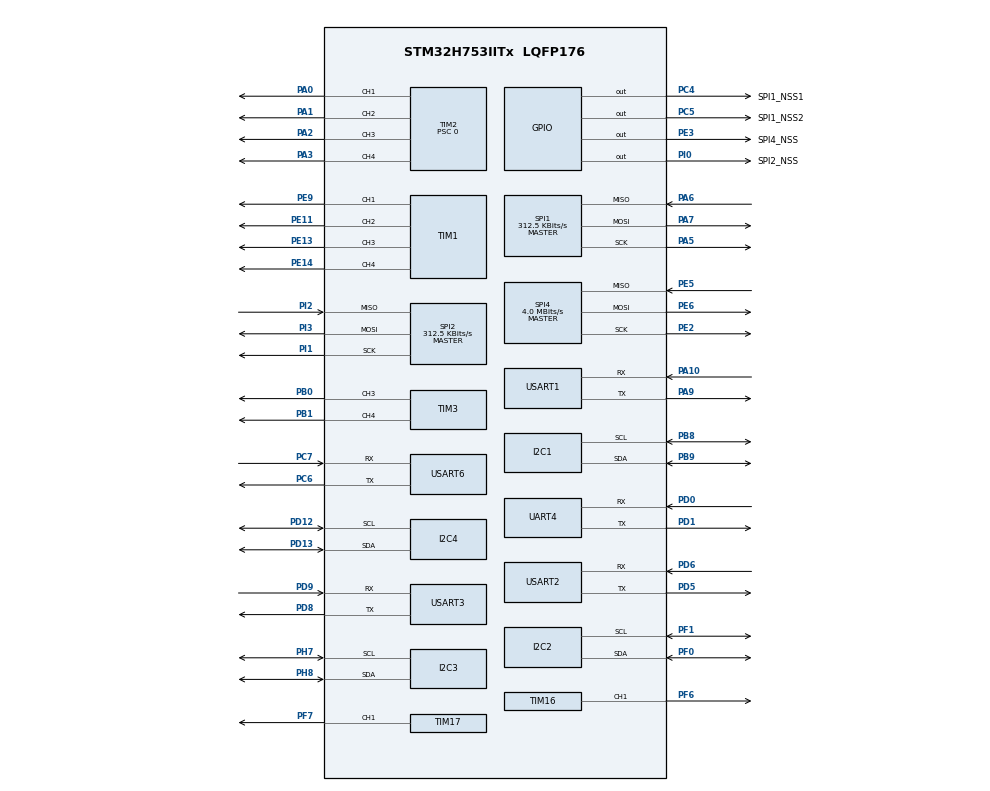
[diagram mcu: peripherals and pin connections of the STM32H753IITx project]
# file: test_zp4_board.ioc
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CORTEX_M7.default_mode_Activation=1
I2C1.I2C_Fall_Time=100
I2C1.I2C_Rise_Time=100
I2C1.Timing=0x00B07CB4
I2C2.I2C_Fall_Time=100
I2C2.I2C_Rise_Time=100
I2C2.Timing=0x00B07CB4
I2C3.I2C_Fall_Time=100
I2C3.I2C_Rise_Time=100
I2C3.Timing=0x00B07CB4
I2C4.I2C_Fall_Time=100
I2C4.I2C_Rise_Time=100
I2C4.Timing=0x00B07CB4
Mcu.Family=STM32H7
Mcu.Name=STM32H753IITx
Mcu.Package=LQFP176
NVIC.PriorityGroup=NVIC_PRIORITYGROUP_4
PA0.Signal=S_TIM2_CH1_ETR
PA1.Signal=S_TIM2_CH2
PA10.Mode=Asynchronous
PA10.Signal=USART1_RX
PA13\ (JTMS/SWDIO).Mode=Trace_Asynchronous_SW
PA13\ (JTMS/SWDIO).Signal=DEBUG_JTMS-SWDIO
PA14\ (JTCK/SWCLK).Mode=Trace_Asynchronous_SW
PA14\ (JTCK/SWCLK).Signal=DEBUG_JTCK-SWCLK
PA2.Signal=S_TIM2_CH3
PA3.Signal=S_TIM2_CH4
PA5.Mode=Full_Duplex_Master
PA5.Signal=SPI1_SCK
PA6.Mode=Full_Duplex_Master
PA6.Signal=SPI1_MISO
PA7.Mode=Full_Duplex_Master
PA7.Signal=SPI1_MOSI
PA9.Mode=Asynchronous
PA9.Signal=USART1_TX
PB0.Signal=S_TIM3_CH3
PB1.Signal=S_TIM3_CH4
PB3\ (JTDO/TRACESWO).Mode=Trace_Asynchronous_SW
PB3\ (JTDO/TRACESWO).Signal=DEBUG_JTDO-SWO
PB8.Mode=I2C
PB8.Signal=I2C1_SCL
PB9.Mode=I2C
PB9.Signal=I2C1_SDA
PC4.GPIO_Label=SPI1_NSS1
PC4.PinState=GPIO_PIN_SET
PC4.Signal=GPIO_Output
PC5.GPIO_Label=SPI1_NSS2
PC5.PinState=GPIO_PIN_SET
PC5.Signal=GPIO_Output
PC6.Mode=Asynchronous
PC6.Signal=USART6_TX
PC7.Mode=Asynchronous
PC7.Signal=USART6_RX
PD0.Mode=Asynchronous
PD0.Signal=UART4_RX
PD1.Mode=Asynchronous
PD1.Signal=UART4_TX
PD12.Mode=I2C
PD12.Signal=I2C4_SCL
PD13.Mode=I2C
PD13.Signal=I2C4_SDA
PD5.Mode=Asynchronous
PD5.Signal=USART2_TX
PD6.Mode=Asynchronous
PD6.Signal=USART2_RX
PD8.Mode=Asynchronous
PD8.Signal=USART3_TX
PD9.Mode=Asynchronous
PD9.Signal=USART3_RX
PE11.Signal=S_TIM1_CH2
PE13.Signal=S_TIM1_CH3
PE14.Signal=S_TIM1_CH4
PE2.Mode=Full_Duplex_Master
PE2.Signal=SPI4_SCK
PE3.GPIO_Label=SPI4_NSS
PE3.PinState=GPIO_PIN_SET
PE3.Signal=GPIO_Output
PE5.Mode=Full_Duplex_Master
PE5.Signal=SPI4_MISO
PE6.Mode=Full_Duplex_Master
PE6.Signal=SPI4_MOSI
PE9.Signal=S_TIM1_CH1
PF0.Mode=I2C
PF0.Signal=I2C2_SDA
PF1.Mode=I2C
PF1.Signal=I2C2_SCL
PF6.Signal=S_TIM16_CH1
PF7.Signal=S_TIM17_CH1
PH7.Mode=I2C
PH7.Signal=I2C3_SCL
PH8.Mode=I2C
PH8.Signal=I2C3_SDA
PI0.GPIO_Label=SPI2_NSS
PI0.PinState=GPIO_PIN_SET
PI0.Signal=GPIO_Output
PI1.Mode=Full_Duplex_Master
PI1.Signal=SPI2_SCK
PI2.Mode=Full_Duplex_Master
PI2.Signal=SPI2_MISO
PI3.Mode=Full_Duplex_Master
PI3.Signal=SPI2_MOSI
ProjectManager.HeapSize=0x200
ProjectManager.StackSize=0x400
ProjectManager.TargetToolchain=STM32CubeIDE
RCC.ADCFreq_Value=129000000
RCC.APB1Freq_Value=32000000
RCC.APB2Freq_Value=32000000
RCC.APB3Freq_Value=64000000
RCC.APB4Freq_Value=32000000
RCC.CortexFreq_Value=64000000
RCC.D2PPRE1=RCC_APB1_DIV2
RCC.D2PPRE2=RCC_APB2_DIV2
RCC.D3PPRE=RCC_APB4_DIV2
RCC.DATA_CACHE_ENABLE=0
RCC.DIVM1=4
RCC.DIVN1=10
RCC.HCLKFreq_Value=64000000
RCC.INSTRUCTION_CACHE_ENABLE=0
RCC.MSIAutoCalibration=DISABLED
RCC.MSICalibrationValue=0
RCC.PLLFRACN=0
RCC.PREFETCH_ENABLE=1
RCC.SYSCLKFreq_VALUE=64000000
RCC.USBFreq_Value=80000000
SH.S_TIM16_CH1.0=TIM16_CH1,PWM Generation1 CH1
SH.S_TIM17_CH1.0=TIM17_CH1,Output Compare1 CH1
SH.S_TIM1_CH1.0=TIM1_CH1,PWM Generation1 CH1
SH.S_TIM1_CH2.0=TIM1_CH2,PWM Generation2 CH2
SH.S_TIM1_CH3.0=TIM1_CH3,PWM Generation3 CH3
SH.S_TIM1_CH4.0=TIM1_CH4,PWM Generation4 CH4
SH.S_TIM2_CH1_ETR.0=TIM2_CH1,PWM Generation1 CH1
SH.S_TIM2_CH2.0=TIM2_CH2,PWM Generation2 CH2
SH.S_TIM2_CH3.0=TIM2_CH3,PWM Generation3 CH3
SH.S_TIM2_CH4.0=TIM2_CH4,PWM Generation4 CH4
SH.S_TIM3_CH3.0=TIM3_CH3,PWM Generation3 CH3
SH.S_TIM3_CH4.0=TIM3_CH4,PWM Generation4 CH4
SPI1.BaudRatePrescaler=SPI_BAUDRATEPRESCALER_256
SPI1.CalculateBaudRate=312.5 KBits/s
SPI1.DataSize=SPI_DATASIZE_8BIT
SPI1.Direction=SPI_DIRECTION_2LINES
SPI1.Mode=SPI_MODE_MASTER
SPI1.VirtualType=VM_MASTER
SPI2.BaudRatePrescaler=SPI_BAUDRATEPRESCALER_256
SPI2.CalculateBaudRate=312.5 KBits/s
SPI2.DataSize=SPI_DATASIZE_8BIT
SPI2.Direction=SPI_DIRECTION_2LINES
SPI2.Mode=SPI_MODE_MASTER
SPI2.VirtualType=VM_MASTER
SPI4.BaudRatePrescaler=SPI_BAUDRATEPRESCALER_8
SPI4.CLKPhase=SPI_PHASE_2EDGE
SPI4.CLKPolarity=SPI_POLARITY_HIGH
SPI4.CalculateBaudRate=4.0 MBits/s
SPI4.DataSize=SPI_DATASIZE_8BIT
SPI4.Direction=SPI_DIRECTION_2LINES
SPI4.FirstBit=SPI_FIRSTBIT_LSB
SPI4.Mode=SPI_MODE_MASTER
SPI4.VirtualType=VM_MASTER
TIM1.Channel-PWM\ Generation1\ CH1=TIM_CHANNEL_1
TIM1.Channel-PWM\ Generation2\ CH2=TIM_CHANNEL_2
TIM1.Channel-PWM\ Generation3\ CH3=TIM_CHANNEL_3
TIM1.Channel-PWM\ Generation4\ CH4=TIM_CHANNEL_4
TIM16.Channel=TIM_CHANNEL_1
TIM17.Channel=TIM_CHANNEL_1
TIM2.Channel-PWM\ Generation1\ CH1=TIM_CHANNEL_1
TIM2.Channel-PWM\ Generation2\ CH2=TIM_CHANNEL_2
TIM2.Channel-PWM\ Generation3\ CH3=TIM_CHANNEL_3
TIM2.Channel-PWM\ Generation4\ CH4=TIM_CHANNEL_4
TIM2.Prescaler=0
TIM3.Channel-PWM\ Generation3\ CH3=TIM_CHANNEL_3
TIM3.Channel-PWM\ Generation4\ CH4=TIM_CHANNEL_4
USART1.VirtualMode-Asynchronous=VM_ASYNC
USART2.VirtualMode-Asynchronous=VM_ASYNC
USART3.VirtualMode-Asynchronous=VM_ASYNC
USART6.VirtualMode-Asynchronous=VM_ASYNC
VP_MEMORYMAP_VS_MEMORYMAP.Mode=CurAppReg
VP_TIM16_VS_ClockSourceINT.Mode=Enable_Timer
VP_TIM17_VS_ClockSourceINT.Mode=Enable_Timer
VP_TIM1_VS_ClockSourceINT.Mode=Internal
VP_TIM2_VS_ClockSourceINT.Mode=Internal
VP_TIM3_VS_ClockSourceINT.Mode=Internal
board=custom

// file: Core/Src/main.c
/* USER CODE BEGIN Header */
/**
  ******************************************************************************
  * @file           : main.c
  * @brief          : Main program body
  ******************************************************************************
  * @attention
  *
  * Copyright (c) 2025 STMicroelectronics.
  * All rights reserved.
  *
  * This software is licensed under terms that can be found in the LICENSE file
  * in the root directory of this software component.
  * If no LICENSE file comes with this software, it is provided AS-IS.
  *
  ******************************************************************************
  */
/* USER CODE END Header */
#include "main.h"

I2C_HandleTypeDef hi2c1;
I2C_HandleTypeDef hi2c2;
I2C_HandleTypeDef hi2c3;
I2C_HandleTypeDef hi2c4;

SPI_HandleTypeDef hspi1;
SPI_HandleTypeDef hspi2;
SPI_HandleTypeDef hspi4;

TIM_HandleTypeDef htim1;
TIM_HandleTypeDef htim2;
TIM_HandleTypeDef htim3;
TIM_HandleTypeDef htim16;
TIM_HandleTypeDef htim17;

UART_HandleTypeDef huart4;
UART_HandleTypeDef huart1;
UART_HandleTypeDef huart2;
UART_HandleTypeDef huart3;
UART_HandleTypeDef huart6;

void SystemClock_Config(void);
static void MPU_Config(void);
static void MX_GPIO_Init(void);
static void MX_I2C1_Init(void);
static void MX_I2C2_Init(void);
static void MX_I2C3_Init(void);
static void MX_TIM1_Init(void);
static void MX_TIM2_Init(void);
static void MX_TIM3_Init(void);
static void MX_UART4_Init(void);
static void MX_USART1_UART_Init(void);
static void MX_USART2_UART_Init(void);
static void MX_USART3_UART_Init(void);
static void MX_USART6_UART_Init(void);
static void MX_SPI1_Init(void);
static void MX_SPI2_Init(void);
static void MX_SPI4_Init(void);
static void MX_TIM16_Init(void);
static void MX_TIM17_Init(void);
static void MX_I2C4_Init(void);

int main(void)
{

  /* MPU Configuration--------------------------------------------------------*/
  MPU_Config();

  /* MCU Configuration--------------------------------------------------------*/

  /* Reset of all peripherals, Initializes the Flash interface and the Systick. */
  HAL_Init();

  /* Configure the system clock */
  SystemClock_Config();

  /* Initialize all configured peripherals */
  MX_GPIO_Init();
  MX_I2C1_Init();
  MX_I2C2_Init();
  MX_I2C3_Init();
  MX_TIM1_Init();
  MX_TIM2_Init();
  MX_TIM3_Init();
  MX_UART4_Init();
  MX_USART1_UART_Init();
  MX_USART2_UART_Init();
  MX_USART3_UART_Init();
  MX_USART6_UART_Init();
  MX_SPI1_Init();
  MX_SPI2_Init();
  MX_SPI4_Init();
  MX_TIM16_Init();
  MX_TIM17_Init();
  MX_I2C4_Init();
  /* USER CODE BEGIN 2 */
  //testTimers();
  /* USER CODE END 2 */

  /* Infinite loop */
  /* USER CODE BEGIN WHILE */
  while (1)
  {
	  //testI2CTx(&hi2c1);    //I2C Testing (Transmit)
	  //testI2CRx(&hi2c1);    //I2C Testing (Receive)

	  // Example: testing SPI1 with two different slaves
	  //testSPI(&hspi1, SPI1_NSS1_GPIO_Port, SPI1_NSS1_Pin);
	  //testSPI(&hspi1, SPI1_NSS2_GPIO_Port, SPI1_NSS2_Pin);
	  //testSPI(&hspi2, SPI2_NSS_GPIO_Port, SPI2_NSS_Pin);
	  //testSPI(&hspi4, SPI4_NSS_GPIO_Port, SPI4_NSS_Pin);
	  //testUART(&huart4);
	  HAL_Delay(1000);
    /* USER CODE END WHILE */

  }
}

void SystemClock_Config(void)
{
  RCC_OscInitTypeDef RCC_OscInitStruct = {0};
  RCC_ClkInitTypeDef RCC_ClkInitStruct = {0};

  /** Supply configuration update enable
  */
  HAL_PWREx_ConfigSupply(PWR_LDO_SUPPLY);

  /** Configure the main internal regulator output voltage
  */
  __HAL_PWR_VOLTAGESCALING_CONFIG(PWR_REGULATOR_VOLTAGE_SCALE3);

  while(!__HAL_PWR_GET_FLAG(PWR_FLAG_VOSRDY)) {}

  /** Initializes the RCC Oscillators according to the specified parameters
  * in the RCC_OscInitTypeDef structure.
  */
  RCC_OscInitStruct.OscillatorType = RCC_OSCILLATORTYPE_HSI;
  RCC_OscInitStruct.HSIState = RCC_HSI_DIV1;
  RCC_OscInitStruct.HSICalibrationValue = RCC_HSICALIBRATION_DEFAULT;
  RCC_OscInitStruct.PLL.PLLState = RCC_PLL_ON;
  RCC_OscInitStruct.PLL.PLLSource = RCC_PLLSOURCE_HSI;
  RCC_OscInitStruct.PLL.PLLM = 4;
  RCC_OscInitStruct.PLL.PLLN = 10;
  RCC_OscInitStruct.PLL.PLLP = 2;
  RCC_OscInitStruct.PLL.PLLQ = 2;
  RCC_OscInitStruct.PLL.PLLR = 2;
  RCC_OscInitStruct.PLL.PLLRGE = RCC_PLL1VCIRANGE_3;
  RCC_OscInitStruct.PLL.PLLVCOSEL = RCC_PLL1VCOMEDIUM;
  RCC_OscInitStruct.PLL.PLLFRACN = 0;
  if (HAL_RCC_OscConfig(&RCC_OscInitStruct) != HAL_OK)
  {
    Error_Handler();
  }

  /** Initializes the CPU, AHB and APB buses clocks
  */
  RCC_ClkInitStruct.ClockType = RCC_CLOCKTYPE_HCLK|RCC_CLOCKTYPE_SYSCLK
                              |RCC_CLOCKTYPE_PCLK1|RCC_CLOCKTYPE_PCLK2
                              |RCC_CLOCKTYPE_D3PCLK1|RCC_CLOCKTYPE_D1PCLK1;
  RCC_ClkInitStruct.SYSCLKSource = RCC_SYSCLKSOURCE_HSI;
  RCC_ClkInitStruct.SYSCLKDivider = RCC_SYSCLK_DIV1;
  RCC_ClkInitStruct.AHBCLKDivider = RCC_HCLK_DIV1;
  RCC_ClkInitStruct.APB3CLKDivider = RCC_APB3_DIV1;
  RCC_ClkInitStruct.APB1CLKDivider = RCC_APB1_DIV2;
  RCC_ClkInitStruct.APB2CLKDivider = RCC_APB2_DIV2;
  RCC_ClkInitStruct.APB4CLKDivider = RCC_APB4_DIV2;

  if (HAL_RCC_ClockConfig(&RCC_ClkInitStruct, FLASH_LATENCY_1) != HAL_OK)
  {
    Error_Handler();
  }
}

static void MX_I2C1_Init(void)
{

  hi2c1.Instance = I2C1;
  hi2c1.Init.Timing = 0x00B07CB4;
  hi2c1.Init.OwnAddress1 = 0;
  hi2c1.Init.AddressingMode = I2C_ADDRESSINGMODE_7BIT;
  hi2c1.Init.DualAddressMode = I2C_DUALADDRESS_DISABLE;
  hi2c1.Init.OwnAddress2 = 0;
  hi2c1.Init.OwnAddress2Masks = I2C_OA2_NOMASK;
  hi2c1.Init.GeneralCallMode = I2C_GENERALCALL_DISABLE;
  hi2c1.Init.NoStretchMode = I2C_NOSTRETCH_DISABLE;
  if (HAL_I2C_Init(&hi2c1) != HAL_OK)
  {
    Error_Handler();
  }

  /** Configure Analogue filter
  */
  if (HAL_I2CEx_ConfigAnalogFilter(&hi2c1, I2C_ANALOGFILTER_ENABLE) != HAL_OK)
  {
    Error_Handler();
  }

  /** Configure Digital filter
  */
  if (HAL_I2CEx_ConfigDigitalFilter(&hi2c1, 0) != HAL_OK)
  {
    Error_Handler();
  }

}

static void MX_I2C2_Init(void)
{

  hi2c2.Instance = I2C2;
  hi2c2.Init.Timing = 0x00B07CB4;
  hi2c2.Init.OwnAddress1 = 0;
  hi2c2.Init.AddressingMode = I2C_ADDRESSINGMODE_7BIT;
  hi2c2.Init.DualAddressMode = I2C_DUALADDRESS_DISABLE;
  hi2c2.Init.OwnAddress2 = 0;
  hi2c2.Init.OwnAddress2Masks = I2C_OA2_NOMASK;
  hi2c2.Init.GeneralCallMode = I2C_GENERALCALL_DISABLE;
  hi2c2.Init.NoStretchMode = I2C_NOSTRETCH_DISABLE;
  if (HAL_I2C_Init(&hi2c2) != HAL_OK)
  {
    Error_Handler();
  }

  /** Configure Analogue filter
  */
  if (HAL_I2CEx_ConfigAnalogFilter(&hi2c2, I2C_ANALOGFILTER_ENABLE) != HAL_OK)
  {
    Error_Handler();
  }

  /** Configure Digital filter
  */
  if (HAL_I2CEx_ConfigDigitalFilter(&hi2c2, 0) != HAL_OK)
  {
    Error_Handler();
  }

}

static void MX_I2C3_Init(void)
{

  hi2c3.Instance = I2C3;
  hi2c3.Init.Timing = 0x00B07CB4;
  hi2c3.Init.OwnAddress1 = 0;
  hi2c3.Init.AddressingMode = I2C_ADDRESSINGMODE_7BIT;
  hi2c3.Init.DualAddressMode = I2C_DUALADDRESS_DISABLE;
  hi2c3.Init.OwnAddress2 = 0;
  hi2c3.Init.OwnAddress2Masks = I2C_OA2_NOMASK;
  hi2c3.Init.GeneralCallMode = I2C_GENERALCALL_DISABLE;
  hi2c3.Init.NoStretchMode = I2C_NOSTRETCH_DISABLE;
  if (HAL_I2C_Init(&hi2c3) != HAL_OK)
  {
    Error_Handler();
  }

  /** Configure Analogue filter
  */
  if (HAL_I2CEx_ConfigAnalogFilter(&hi2c3, I2C_ANALOGFILTER_ENABLE) != HAL_OK)
  {
    Error_Handler();
  }

  /** Configure Digital filter
  */
  if (HAL_I2CEx_ConfigDigitalFilter(&hi2c3, 0) != HAL_OK)
  {
    Error_Handler();
  }

}

static void MX_I2C4_Init(void)
{

  hi2c4.Instance = I2C4;
  hi2c4.Init.Timing = 0x00B07CB4;
  hi2c4.Init.OwnAddress1 = 0;
  hi2c4.Init.AddressingMode = I2C_ADDRESSINGMODE_7BIT;
  hi2c4.Init.DualAddressMode = I2C_DUALADDRESS_DISABLE;
  hi2c4.Init.OwnAddress2 = 0;
  hi2c4.Init.OwnAddress2Masks = I2C_OA2_NOMASK;
  hi2c4.Init.GeneralCallMode = I2C_GENERALCALL_DISABLE;
  hi2c4.Init.NoStretchMode = I2C_NOSTRETCH_DISABLE;
  if (HAL_I2C_Init(&hi2c4) != HAL_OK)
  {
    Error_Handler();
  }

  /** Configure Analogue filter
  */
  if (HAL_I2CEx_ConfigAnalogFilter(&hi2c4, I2C_ANALOGFILTER_ENABLE) != HAL_OK)
  {
    Error_Handler();
  }

  /** Configure Digital filter
  */
  if (HAL_I2CEx_ConfigDigitalFilter(&hi2c4, 0) != HAL_OK)
  {
    Error_Handler();
  }

}

static void MX_SPI1_Init(void)
{

  /* SPI1 parameter configuration*/
  hspi1.Instance = SPI1;
  hspi1.Init.Mode = SPI_MODE_MASTER;
  hspi1.Init.Direction = SPI_DIRECTION_2LINES;
  hspi1.Init.DataSize = SPI_DATASIZE_8BIT;
  hspi1.Init.CLKPolarity = SPI_POLARITY_LOW;
  hspi1.Init.CLKPhase = SPI_PHASE_1EDGE;
  hspi1.Init.NSS = SPI_NSS_SOFT;
  hspi1.Init.BaudRatePrescaler = SPI_BAUDRATEPRESCALER_256;
  hspi1.Init.FirstBit = SPI_FIRSTBIT_MSB;
  hspi1.Init.TIMode = SPI_TIMODE_DISABLE;
  hspi1.Init.CRCCalculation = SPI_CRCCALCULATION_DISABLE;
  hspi1.Init.CRCPolynomial = 0x0;
  hspi1.Init.NSSPMode = SPI_NSS_PULSE_ENABLE;
  hspi1.Init.NSSPolarity = SPI_NSS_POLARITY_LOW;
  hspi1.Init.FifoThreshold = SPI_FIFO_THRESHOLD_01DATA;
  hspi1.Init.TxCRCInitializationPattern = SPI_CRC_INITIALIZATION_ALL_ZERO_PATTERN;
  hspi1.Init.RxCRCInitializationPattern = SPI_CRC_INITIALIZATION_ALL_ZERO_PATTERN;
  hspi1.Init.MasterSSIdleness = SPI_MASTER_SS_IDLENESS_00CYCLE;
  hspi1.Init.MasterInterDataIdleness = SPI_MASTER_INTERDATA_IDLENESS_00CYCLE;
  hspi1.Init.MasterReceiverAutoSusp = SPI_MASTER_RX_AUTOSUSP_DISABLE;
  hspi1.Init.MasterKeepIOState = SPI_MASTER_KEEP_IO_STATE_DISABLE;
  hspi1.Init.IOSwap = SPI_IO_SWAP_DISABLE;
  if (HAL_SPI_Init(&hspi1) != HAL_OK)
  {
    Error_Handler();
  }

}

static void MX_SPI2_Init(void)
{

  /* SPI2 parameter configuration*/
  hspi2.Instance = SPI2;
  hspi2.Init.Mode = SPI_MODE_MASTER;
  hspi2.Init.Direction = SPI_DIRECTION_2LINES;
  hspi2.Init.DataSize = SPI_DATASIZE_8BIT;
  hspi2.Init.CLKPolarity = SPI_POLARITY_LOW;
  hspi2.Init.CLKPhase = SPI_PHASE_1EDGE;
  hspi2.Init.NSS = SPI_NSS_SOFT;
  hspi2.Init.BaudRatePrescaler = SPI_BAUDRATEPRESCALER_256;
  hspi2.Init.FirstBit = SPI_FIRSTBIT_MSB;
  hspi2.Init.TIMode = SPI_TIMODE_DISABLE;
  hspi2.Init.CRCCalculation = SPI_CRCCALCULATION_DISABLE;
  hspi2.Init.CRCPolynomial = 0x0;
  hspi2.Init.NSSPMode = SPI_NSS_PULSE_ENABLE;
  hspi2.Init.NSSPolarity = SPI_NSS_POLARITY_LOW;
  hspi2.Init.FifoThreshold = SPI_FIFO_THRESHOLD_01DATA;
  hspi2.Init.TxCRCInitializationPattern = SPI_CRC_INITIALIZATION_ALL_ZERO_PATTERN;
  hspi2.Init.RxCRCInitializationPattern = SPI_CRC_INITIALIZATION_ALL_ZERO_PATTERN;
  hspi2.Init.MasterSSIdleness = SPI_MASTER_SS_IDLENESS_00CYCLE;
  hspi2.Init.MasterInterDataIdleness = SPI_MASTER_INTERDATA_IDLENESS_00CYCLE;
  hspi2.Init.MasterReceiverAutoSusp = SPI_MASTER_RX_AUTOSUSP_DISABLE;
  hspi2.Init.MasterKeepIOState = SPI_MASTER_KEEP_IO_STATE_DISABLE;
  hspi2.Init.IOSwap = SPI_IO_SWAP_DISABLE;
  if (HAL_SPI_Init(&hspi2) != HAL_OK)
  {
    Error_Handler();
  }

}

static void MX_SPI4_Init(void)
{

  /* SPI4 parameter configuration*/
  hspi4.Instance = SPI4;
  hspi4.Init.Mode = SPI_MODE_MASTER;
  hspi4.Init.Direction = SPI_DIRECTION_2LINES;
  hspi4.Init.DataSize = SPI_DATASIZE_8BIT;
  hspi4.Init.CLKPolarity = SPI_POLARITY_HIGH;
  hspi4.Init.CLKPhase = SPI_PHASE_2EDGE;
  hspi4.Init.NSS = SPI_NSS_SOFT;
  hspi4.Init.BaudRatePrescaler = SPI_BAUDRATEPRESCALER_8;
  hspi4.Init.FirstBit = SPI_FIRSTBIT_LSB;
  hspi4.Init.TIMode = SPI_TIMODE_DISABLE;
  hspi4.Init.CRCCalculation = SPI_CRCCALCULATION_DISABLE;
  hspi4.Init.CRCPolynomial = 0x0;
  hspi4.Init.NSSPMode = SPI_NSS_PULSE_ENABLE;
  hspi4.Init.NSSPolarity = SPI_NSS_POLARITY_LOW;
  hspi4.Init.FifoThreshold = SPI_FIFO_THRESHOLD_01DATA;
  hspi4.Init.TxCRCInitializationPattern = SPI_CRC_INITIALIZATION_ALL_ZERO_PATTERN;
  hspi4.Init.RxCRCInitializationPattern = SPI_CRC_INITIALIZATION_ALL_ZERO_PATTERN;
  hspi4.Init.MasterSSIdleness = SPI_MASTER_SS_IDLENESS_00CYCLE;
  hspi4.Init.MasterInterDataIdleness = SPI_MASTER_INTERDATA_IDLENESS_00CYCLE;
  hspi4.Init.MasterReceiverAutoSusp = SPI_MASTER_RX_AUTOSUSP_DISABLE;
  hspi4.Init.MasterKeepIOState = SPI_MASTER_KEEP_IO_STATE_DISABLE;
  hspi4.Init.IOSwap = SPI_IO_SWAP_DISABLE;
  if (HAL_SPI_Init(&hspi4) != HAL_OK)
  {
    Error_Handler();
  }

}

static void MX_TIM1_Init(void)
{

  TIM_ClockConfigTypeDef sClockSourceConfig = {0};
  TIM_MasterConfigTypeDef sMasterConfig = {0};
  TIM_OC_InitTypeDef sConfigOC = {0};
  TIM_BreakDeadTimeConfigTypeDef sBreakDeadTimeConfig = {0};

  htim1.Instance = TIM1;
  htim1.Init.Prescaler = 0;
  htim1.Init.CounterMode = TIM_COUNTERMODE_UP;
  htim1.Init.Period = 65535;
  htim1.Init.ClockDivision = TIM_CLOCKDIVISION_DIV1;
  htim1.Init.RepetitionCounter = 0;
  htim1.Init.AutoReloadPreload = TIM_AUTORELOAD_PRELOAD_DISABLE;
  if (HAL_TIM_Base_Init(&htim1) != HAL_OK)
  {
    Error_Handler();
  }
  sClockSourceConfig.ClockSource = TIM_CLOCKSOURCE_INTERNAL;
  if (HAL_TIM_ConfigClockSource(&htim1, &sClockSourceConfig) != HAL_OK)
  {
    Error_Handler();
  }
  if (HAL_TIM_PWM_Init(&htim1) != HAL_OK)
  {
    Error_Handler();
  }
  sMasterConfig.MasterOutputTrigger = TIM_TRGO_RESET;
  sMasterConfig.MasterOutputTrigger2 = TIM_TRGO2_RESET;
  sMasterConfig.MasterSlaveMode = TIM_MASTERSLAVEMODE_DISABLE;
  if (HAL_TIMEx_MasterConfigSynchronization(&htim1, &sMasterConfig) != HAL_OK)
  {
    Error_Handler();
  }
  sConfigOC.OCMode = TIM_OCMODE_PWM1;
  sConfigOC.Pulse = 0;
  sConfigOC.OCPolarity = TIM_OCPOLARITY_HIGH;
  sConfigOC.OCNPolarity = TIM_OCNPOLARITY_HIGH;
  sConfigOC.OCFastMode = TIM_OCFAST_DISABLE;
  sConfigOC.OCIdleState = TIM_OCIDLESTATE_RESET;
  sConfigOC.OCNIdleState = TIM_OCNIDLESTATE_RESET;
  if (HAL_TIM_PWM_ConfigChannel(&htim1, &sConfigOC, TIM_CHANNEL_1) != HAL_OK)
  {
    Error_Handler();
  }
  if (HAL_TIM_PWM_ConfigChannel(&htim1, &sConfigOC, TIM_CHANNEL_2) != HAL_OK)
  {
    Error_Handler();
  }
  if (HAL_TIM_PWM_ConfigChannel(&htim1, &sConfigOC, TIM_CHANNEL_3) != HAL_OK)
  {
    Error_Handler();
  }
  if (HAL_TIM_PWM_ConfigChannel(&htim1, &sConfigOC, TIM_CHANNEL_4) != HAL_OK)
  {
    Error_Handler();
  }
  sBreakDeadTimeConfig.OffStateRunMode = TIM_OSSR_DISABLE;
  sBreakDeadTimeConfig.OffStateIDLEMode = TIM_OSSI_DISABLE;
  sBreakDeadTimeConfig.LockLevel = TIM_LOCKLEVEL_OFF;
  sBreakDeadTimeConfig.DeadTime = 0;
  sBreakDeadTimeConfig.BreakState = TIM_BREAK_DISABLE;
  sBreakDeadTimeConfig.BreakPolarity = TIM_BREAKPOLARITY_HIGH;
  sBreakDeadTimeConfig.BreakFilter = 0;
  sBreakDeadTimeConfig.Break2State = TIM_BREAK2_DISABLE;
  sBreakDeadTimeConfig.Break2Polarity = TIM_BREAK2POLARITY_HIGH;
  sBreakDeadTimeConfig.Break2Filter = 0;
  sBreakDeadTimeConfig.AutomaticOutput = TIM_AUTOMATICOUTPUT_DISABLE;
  if (HAL_TIMEx_ConfigBreakDeadTime(&htim1, &sBreakDeadTimeConfig) != HAL_OK)
  {
    Error_Handler();
  }
  HAL_TIM_MspPostInit(&htim1);

}

static void MX_TIM2_Init(void)
{

  TIM_ClockConfigTypeDef sClockSourceConfig = {0};
  TIM_MasterConfigTypeDef sMasterConfig = {0};
  TIM_OC_InitTypeDef sConfigOC = {0};

  htim2.Instance = TIM2;
  htim2.Init.Prescaler = 0;
  htim2.Init.CounterMode = TIM_COUNTERMODE_UP;
  htim2.Init.Period = 4294967295;
  htim2.Init.ClockDivision = TIM_CLOCKDIVISION_DIV1;
  htim2.Init.AutoReloadPreload = TIM_AUTORELOAD_PRELOAD_DISABLE;
  if (HAL_TIM_Base_Init(&htim2) != HAL_OK)
  {
    Error_Handler();
  }
  sClockSourceConfig.ClockSource = TIM_CLOCKSOURCE_INTERNAL;
  if (HAL_TIM_ConfigClockSource(&htim2, &sClockSourceConfig) != HAL_OK)
  {
    Error_Handler();
  }
  if (HAL_TIM_PWM_Init(&htim2) != HAL_OK)
  {
    Error_Handler();
  }
  sMasterConfig.MasterOutputTrigger = TIM_TRGO_RESET;
  sMasterConfig.MasterSlaveMode = TIM_MASTERSLAVEMODE_DISABLE;
  if (HAL_TIMEx_MasterConfigSynchronization(&htim2, &sMasterConfig) != HAL_OK)
  {
    Error_Handler();
  }
  sConfigOC.OCMode = TIM_OCMODE_PWM1;
  sConfigOC.Pulse = 0;
  sConfigOC.OCPolarity = TIM_OCPOLARITY_HIGH;
  sConfigOC.OCFastMode = TIM_OCFAST_DISABLE;
  if (HAL_TIM_PWM_ConfigChannel(&htim2, &sConfigOC, TIM_CHANNEL_1) != HAL_OK)
  {
    Error_Handler();
  }
  if (HAL_TIM_PWM_ConfigChannel(&htim2, &sConfigOC, TIM_CHANNEL_2) != HAL_OK)
  {
    Error_Handler();
  }
  if (HAL_TIM_PWM_ConfigChannel(&htim2, &sConfigOC, TIM_CHANNEL_3) != HAL_OK)
  {
    Error_Handler();
  }
  if (HAL_TIM_PWM_ConfigChannel(&htim2, &sConfigOC, TIM_CHANNEL_4) != HAL_OK)
  {
    Error_Handler();
  }
  HAL_TIM_MspPostInit(&htim2);

}

static void MX_TIM3_Init(void)
{

  TIM_ClockConfigTypeDef sClockSourceConfig = {0};
  TIM_MasterConfigTypeDef sMasterConfig = {0};
  TIM_OC_InitTypeDef sConfigOC = {0};

  htim3.Instance = TIM3;
  htim3.Init.Prescaler = 0;
  htim3.Init.CounterMode = TIM_COUNTERMODE_UP;
  htim3.Init.Period = 65535;
  htim3.Init.ClockDivision = TIM_CLOCKDIVISION_DIV1;
  htim3.Init.AutoReloadPreload = TIM_AUTORELOAD_PRELOAD_DISABLE;
  if (HAL_TIM_Base_Init(&htim3) != HAL_OK)
  {
    Error_Handler();
  }
  sClockSourceConfig.ClockSource = TIM_CLOCKSOURCE_INTERNAL;
  if (HAL_TIM_ConfigClockSource(&htim3, &sClockSourceConfig) != HAL_OK)
  {
    Error_Handler();
  }
  if (HAL_TIM_PWM_Init(&htim3) != HAL_OK)
  {
    Error_Handler();
  }
  sMasterConfig.MasterOutputTrigger = TIM_TRGO_RESET;
  sMasterConfig.MasterSlaveMode = TIM_MASTERSLAVEMODE_DISABLE;
  if (HAL_TIMEx_MasterConfigSynchronization(&htim3, &sMasterConfig) != HAL_OK)
  {
    Error_Handler();
  }
  sConfigOC.OCMode = TIM_OCMODE_PWM1;
  sConfigOC.Pulse = 0;
  sConfigOC.OCPolarity = TIM_OCPOLARITY_HIGH;
  sConfigOC.OCFastMode = TIM_OCFAST_DISABLE;
  if (HAL_TIM_PWM_ConfigChannel(&htim3, &sConfigOC, TIM_CHANNEL_3) != HAL_OK)
  {
    Error_Handler();
  }
  if (HAL_TIM_PWM_ConfigChannel(&htim3, &sConfigOC, TIM_CHANNEL_4) != HAL_OK)
  {
    Error_Handler();
  }
  HAL_TIM_MspPostInit(&htim3);

}

static void MX_TIM16_Init(void)
{

  TIM_OC_InitTypeDef sConfigOC = {0};
  TIM_BreakDeadTimeConfigTypeDef sBreakDeadTimeConfig = {0};

  htim16.Instance = TIM16;
  htim16.Init.Prescaler = 0;
  htim16.Init.CounterMode = TIM_COUNTERMODE_UP;
  htim16.Init.Period = 65535;
  htim16.Init.ClockDivision = TIM_CLOCKDIVISION_DIV1;
  htim16.Init.RepetitionCounter = 0;
  htim16.Init.AutoReloadPreload = TIM_AUTORELOAD_PRELOAD_DISABLE;
  if (HAL_TIM_Base_Init(&htim16) != HAL_OK)
  {
    Error_Handler();
  }
  if (HAL_TIM_PWM_Init(&htim16) != HAL_OK)
  {
    Error_Handler();
  }
  sConfigOC.OCMode = TIM_OCMODE_PWM1;
  sConfigOC.Pulse = 0;
  sConfigOC.OCPolarity = TIM_OCPOLARITY_HIGH;
  sConfigOC.OCNPolarity = TIM_OCNPOLARITY_HIGH;
  sConfigOC.OCFastMode = TIM_OCFAST_DISABLE;
  sConfigOC.OCIdleState = TIM_OCIDLESTATE_RESET;
  sConfigOC.OCNIdleState = TIM_OCNIDLESTATE_RESET;
  if (HAL_TIM_PWM_ConfigChannel(&htim16, &sConfigOC, TIM_CHANNEL_1) != HAL_OK)
  {
    Error_Handler();
  }
  sBreakDeadTimeConfig.OffStateRunMode = TIM_OSSR_DISABLE;
  sBreakDeadTimeConfig.OffStateIDLEMode = TIM_OSSI_DISABLE;
  sBreakDeadTimeConfig.LockLevel = TIM_LOCKLEVEL_OFF;
  sBreakDeadTimeConfig.DeadTime = 0;
  sBreakDeadTimeConfig.BreakState = TIM_BREAK_DISABLE;
  sBreakDeadTimeConfig.BreakPolarity = TIM_BREAKPOLARITY_HIGH;
  sBreakDeadTimeConfig.BreakFilter = 0;
  sBreakDeadTimeConfig.AutomaticOutput = TIM_AUTOMATICOUTPUT_DISABLE;
  if (HAL_TIMEx_ConfigBreakDeadTime(&htim16, &sBreakDeadTimeConfig) != HAL_OK)
  {
    Error_Handler();
  }
  HAL_TIM_MspPostInit(&htim16);

}

static void MX_TIM17_Init(void)
{

  TIM_OC_InitTypeDef sConfigOC = {0};
  TIM_BreakDeadTimeConfigTypeDef sBreakDeadTimeConfig = {0};

  htim17.Instance = TIM17;
  htim17.Init.Prescaler = 0;
  htim17.Init.CounterMode = TIM_COUNTERMODE_UP;
  htim17.Init.Period = 65535;
  htim17.Init.ClockDivision = TIM_CLOCKDIVISION_DIV1;
  htim17.Init.RepetitionCounter = 0;
  htim17.Init.AutoReloadPreload = TIM_AUTORELOAD_PRELOAD_DISABLE;
  if (HAL_TIM_Base_Init(&htim17) != HAL_OK)
  {
    Error_Handler();
  }
  if (HAL_TIM_OC_Init(&htim17) != HAL_OK)
  {
    Error_Handler();
  }
  sConfigOC.OCMode = TIM_OCMODE_TIMING;
  sConfigOC.Pulse = 0;
  sConfigOC.OCPolarity = TIM_OCPOLARITY_HIGH;
  sConfigOC.OCNPolarity = TIM_OCNPOLARITY_HIGH;
  sConfigOC.OCFastMode = TIM_OCFAST_DISABLE;
  sConfigOC.OCIdleState = TIM_OCIDLESTATE_RESET;
  sConfigOC.OCNIdleState = TIM_OCNIDLESTATE_RESET;
  if (HAL_TIM_OC_ConfigChannel(&htim17, &sConfigOC, TIM_CHANNEL_1) != HAL_OK)
  {
    Error_Handler();
  }
  sBreakDeadTimeConfig.OffStateRunMode = TIM_OSSR_DISABLE;
  sBreakDeadTimeConfig.OffStateIDLEMode = TIM_OSSI_DISABLE;
  sBreakDeadTimeConfig.LockLevel = TIM_LOCKLEVEL_OFF;
  sBreakDeadTimeConfig.DeadTime = 0;
  sBreakDeadTimeConfig.BreakState = TIM_BREAK_DISABLE;
  sBreakDeadTimeConfig.BreakPolarity = TIM_BREAKPOLARITY_HIGH;
  sBreakDeadTimeConfig.BreakFilter = 0;
  sBreakDeadTimeConfig.AutomaticOutput = TIM_AUTOMATICOUTPUT_DISABLE;
  if (HAL_TIMEx_ConfigBreakDeadTime(&htim17, &sBreakDeadTimeConfig) != HAL_OK)
  {
    Error_Handler();
  }
  HAL_TIM_MspPostInit(&htim17);

}

static void MX_UART4_Init(void)
{

  huart4.Instance = UART4;
  huart4.Init.BaudRate = 115200;
  huart4.Init.WordLength = UART_WORDLENGTH_8B;
  huart4.Init.StopBits = UART_STOPBITS_1;
  huart4.Init.Parity = UART_PARITY_NONE;
  huart4.Init.Mode = UART_MODE_TX_RX;
  huart4.Init.HwFlowCtl = UART_HWCONTROL_NONE;
  huart4.Init.OverSampling = UART_OVERSAMPLING_16;
  huart4.Init.OneBitSampling = UART_ONE_BIT_SAMPLE_DISABLE;
  huart4.Init.ClockPrescaler = UART_PRESCALER_DIV1;
  huart4.AdvancedInit.AdvFeatureInit = UART_ADVFEATURE_NO_INIT;
  if (HAL_UART_Init(&huart4) != HAL_OK)
  {
    Error_Handler();
  }
  if (HAL_UARTEx_SetTxFifoThreshold(&huart4, UART_TXFIFO_THRESHOLD_1_8) != HAL_OK)
  {
    Error_Handler();
  }
  if (HAL_UARTEx_SetRxFifoThreshold(&huart4, UART_RXFIFO_THRESHOLD_1_8) != HAL_OK)
  {
    Error_Handler();
  }
  if (HAL_UARTEx_DisableFifoMode(&huart4) != HAL_OK)
  {
    Error_Handler();
  }

}

static void MX_USART1_UART_Init(void)
{

  huart1.Instance = USART1;
  huart1.Init.BaudRate = 115200;
  huart1.Init.WordLength = UART_WORDLENGTH_8B;
  huart1.Init.StopBits = UART_STOPBITS_1;
  huart1.Init.Parity = UART_PARITY_NONE;
  huart1.Init.Mode = UART_MODE_TX_RX;
  huart1.Init.HwFlowCtl = UART_HWCONTROL_NONE;
  huart1.Init.OverSampling = UART_OVERSAMPLING_16;
  huart1.Init.OneBitSampling = UART_ONE_BIT_SAMPLE_DISABLE;
  huart1.Init.ClockPrescaler = UART_PRESCALER_DIV1;
  huart1.AdvancedInit.AdvFeatureInit = UART_ADVFEATURE_NO_INIT;
  if (HAL_UART_Init(&huart1) != HAL_OK)
  {
    Error_Handler();
  }
  if (HAL_UARTEx_SetTxFifoThreshold(&huart1, UART_TXFIFO_THRESHOLD_1_8) != HAL_OK)
  {
    Error_Handler();
  }
  if (HAL_UARTEx_SetRxFifoThreshold(&huart1, UART_RXFIFO_THRESHOLD_1_8) != HAL_OK)
  {
    Error_Handler();
  }
  if (HAL_UARTEx_DisableFifoMode(&huart1) != HAL_OK)
  {
    Error_Handler();
  }

}

static void MX_USART2_UART_Init(void)
{

  huart2.Instance = USART2;
  huart2.Init.BaudRate = 115200;
  huart2.Init.WordLength = UART_WORDLENGTH_8B;
  huart2.Init.StopBits = UART_STOPBITS_1;
  huart2.Init.Parity = UART_PARITY_NONE;
  huart2.Init.Mode = UART_MODE_TX_RX;
  huart2.Init.HwFlowCtl = UART_HWCONTROL_NONE;
  huart2.Init.OverSampling = UART_OVERSAMPLING_16;
  huart2.Init.OneBitSampling = UART_ONE_BIT_SAMPLE_DISABLE;
  huart2.Init.ClockPrescaler = UART_PRESCALER_DIV1;
  huart2.AdvancedInit.AdvFeatureInit = UART_ADVFEATURE_NO_INIT;
  if (HAL_UART_Init(&huart2) != HAL_OK)
  {
    Error_Handler();
  }
  if (HAL_UARTEx_SetTxFifoThreshold(&huart2, UART_TXFIFO_THRESHOLD_1_8) != HAL_OK)
  {
    Error_Handler();
  }
  if (HAL_UARTEx_SetRxFifoThreshold(&huart2, UART_RXFIFO_THRESHOLD_1_8) != HAL_OK)
  {
    Error_Handler();
  }
  if (HAL_UARTEx_DisableFifoMode(&huart2) != HAL_OK)
  {
    Error_Handler();
  }

}

static void MX_USART3_UART_Init(void)
{

  huart3.Instance = USART3;
  huart3.Init.BaudRate = 115200;
  huart3.Init.WordLength = UART_WORDLENGTH_8B;
  huart3.Init.StopBits = UART_STOPBITS_1;
  huart3.Init.Parity = UART_PARITY_NONE;
  huart3.Init.Mode = UART_MODE_TX_RX;
  huart3.Init.HwFlowCtl = UART_HWCONTROL_NONE;
  huart3.Init.OverSampling = UART_OVERSAMPLING_16;
  huart3.Init.OneBitSampling = UART_ONE_BIT_SAMPLE_DISABLE;
  huart3.Init.ClockPrescaler = UART_PRESCALER_DIV1;
  huart3.AdvancedInit.AdvFeatureInit = UART_ADVFEATURE_NO_INIT;
  if (HAL_UART_Init(&huart3) != HAL_OK)
  {
    Error_Handler();
  }
  if (HAL_UARTEx_SetTxFifoThreshold(&huart3, UART_TXFIFO_THRESHOLD_1_8) != HAL_OK)
  {
    Error_Handler();
  }
  if (HAL_UARTEx_SetRxFifoThreshold(&huart3, UART_RXFIFO_THRESHOLD_1_8) != HAL_OK)
  {
    Error_Handler();
  }
  if (HAL_UARTEx_DisableFifoMode(&huart3) != HAL_OK)
  {
    Error_Handler();
  }

}

static void MX_USART6_UART_Init(void)
{

  huart6.Instance = USART6;
  huart6.Init.BaudRate = 115200;
  huart6.Init.WordLength = UART_WORDLENGTH_8B;
  huart6.Init.StopBits = UART_STOPBITS_1;
  huart6.Init.Parity = UART_PARITY_NONE;
  huart6.Init.Mode = UART_MODE_TX_RX;
  huart6.Init.HwFlowCtl = UART_HWCONTROL_NONE;
  huart6.Init.OverSampling = UART_OVERSAMPLING_16;
  huart6.Init.OneBitSampling = UART_ONE_BIT_SAMPLE_DISABLE;
  huart6.Init.ClockPrescaler = UART_PRESCALER_DIV1;
  huart6.AdvancedInit.AdvFeatureInit = UART_ADVFEATURE_NO_INIT;
  if (HAL_UART_Init(&huart6) != HAL_OK)
  {
    Error_Handler();
  }
  if (HAL_UARTEx_SetTxFifoThreshold(&huart6, UART_TXFIFO_THRESHOLD_1_8) != HAL_OK)
  {
    Error_Handler();
  }
  if (HAL_UARTEx_SetRxFifoThreshold(&huart6, UART_RXFIFO_THRESHOLD_1_8) != HAL_OK)
  {
    Error_Handler();
  }
  if (HAL_UARTEx_DisableFifoMode(&huart6) != HAL_OK)
  {
    Error_Handler();
  }

}

static void MX_GPIO_Init(void)
{
  GPIO_InitTypeDef GPIO_InitStruct = {0};

  /* GPIO Ports Clock Enable */
  __HAL_RCC_GPIOE_CLK_ENABLE();
  __HAL_RCC_GPIOF_CLK_ENABLE();
  __HAL_RCC_GPIOA_CLK_ENABLE();
  __HAL_RCC_GPIOC_CLK_ENABLE();
  __HAL_RCC_GPIOB_CLK_ENABLE();
  __HAL_RCC_GPIOH_CLK_ENABLE();
  __HAL_RCC_GPIOD_CLK_ENABLE();
  __HAL_RCC_GPIOI_CLK_ENABLE();

  /*Configure GPIO pin Output Level */
  HAL_GPIO_WritePin(SPI4_NSS_GPIO_Port, SPI4_NSS_Pin, GPIO_PIN_SET);

  /*Configure GPIO pin Output Level */
  HAL_GPIO_WritePin(GPIOC, SPI1_NSS1_Pin|SPI1_NSS2_Pin, GPIO_PIN_SET);

  /*Configure GPIO pin Output Level */
  HAL_GPIO_WritePin(SPI2_NSS_GPIO_Port, SPI2_NSS_Pin, GPIO_PIN_SET);

  /*Configure GPIO pin : SPI4_NSS_Pin */
  GPIO_InitStruct.Pin = SPI4_NSS_Pin;
  GPIO_InitStruct.Mode = GPIO_MODE_OUTPUT_PP;
  GPIO_InitStruct.Pull = GPIO_NOPULL;
  GPIO_InitStruct.Speed = GPIO_SPEED_FREQ_LOW;
  HAL_GPIO_Init(SPI4_NSS_GPIO_Port, &GPIO_InitStruct);

  /*Configure GPIO pins : SPI1_NSS1_Pin SPI1_NSS2_Pin */
  GPIO_InitStruct.Pin = SPI1_NSS1_Pin|SPI1_NSS2_Pin;
  GPIO_InitStruct.Mode = GPIO_MODE_OUTPUT_PP;
  GPIO_InitStruct.Pull = GPIO_NOPULL;
  GPIO_InitStruct.Speed = GPIO_SPEED_FREQ_LOW;
  HAL_GPIO_Init(GPIOC, &GPIO_InitStruct);

  /*Configure GPIO pin : SPI2_NSS_Pin */
  GPIO_InitStruct.Pin = SPI2_NSS_Pin;
  GPIO_InitStruct.Mode = GPIO_MODE_OUTPUT_PP;
  GPIO_InitStruct.Pull = GPIO_NOPULL;
  GPIO_InitStruct.Speed = GPIO_SPEED_FREQ_LOW;
  HAL_GPIO_Init(SPI2_NSS_GPIO_Port, &GPIO_InitStruct);

}

 /* MPU Configuration */

void MPU_Config(void)
{
  MPU_Region_InitTypeDef MPU_InitStruct = {0};

  /* Disables the MPU */
  HAL_MPU_Disable();

  /** Initializes and configures the Region and the memory to be protected
  */
  MPU_InitStruct.Enable = MPU_REGION_ENABLE;
  MPU_InitStruct.Number = MPU_REGION_NUMBER0;
  MPU_InitStruct.BaseAddress = 0x0;
  MPU_InitStruct.Size = MPU_REGION_SIZE_4GB;
  MPU_InitStruct.SubRegionDisable = 0x87;
  MPU_InitStruct.TypeExtField = MPU_TEX_LEVEL0;
  MPU_InitStruct.AccessPermission = MPU_REGION_NO_ACCESS;
  MPU_InitStruct.DisableExec = MPU_INSTRUCTION_ACCESS_DISABLE;
  MPU_InitStruct.IsShareable = MPU_ACCESS_SHAREABLE;
  MPU_InitStruct.IsCacheable = MPU_ACCESS_NOT_CACHEABLE;
  MPU_InitStruct.IsBufferable = MPU_ACCESS_NOT_BUFFERABLE;

  HAL_MPU_ConfigRegion(&MPU_InitStruct);
  /* Enables the MPU */
  HAL_MPU_Enable(MPU_PRIVILEGED_DEFAULT);

}

void Error_Handler(void)
{
  __disable_irq();
  while (1)
  {
  }
}
